# STM32H743 register map
File version: 2.4
CPU: CM7 r0p1, little endian, MPU, FPU, 4 interrupt priority bits
Registers are 32-bit, read-write, reset 0x0 unless marked. A register's access mark holds for its fields unless they carry their own. Offsets are from the block's base; [hi:lo] are bit positions; 'fields as' and 'values as' point back to an identical list.

## Flash — 闪存控制器
Base 0x52002000
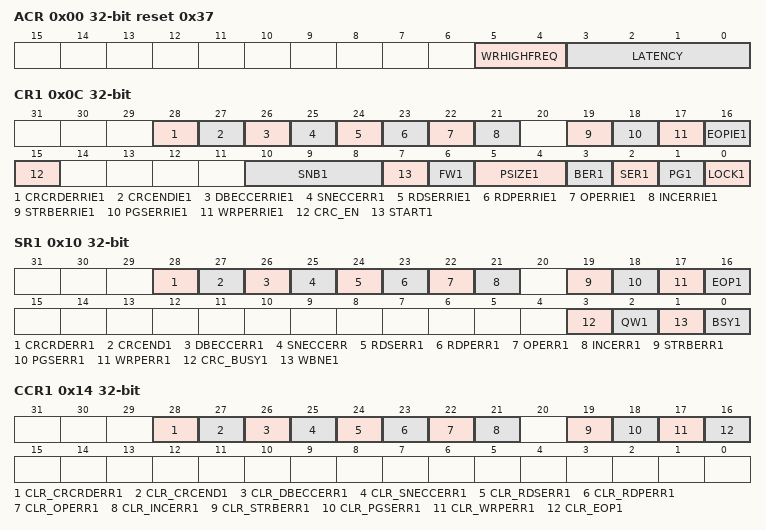
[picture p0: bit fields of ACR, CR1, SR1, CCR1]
0x00 ACR reset 0x37 — 访问控制寄存器
  [5:4] WRHIGHFREQ — 闪存信号延迟
  [3:0] LATENCY — 读延迟（等待周期）
0x04 KEYR1 — 闪存密钥寄存器（Bank 1）
  [31:0] KEY1R — Bank 1 访问配置解锁密钥
0x08 OPTKEYR — 闪存选项密钥寄存器
  [31:0] OPTKEYR — 选项字节解锁密钥
0x0C CR1 — 闪存控制寄存器（Bank 1）
  [28] CRCRDERRIE1 — Bank 1 CRC 读取错误中断使能位。当 CRCRDERRIE1 位置 1 时，若在 Bank 1 上一次 CRC 计算过程中检测到受保护区域（PCROP 或仅安全区域），则产生中断。仅当 LOCK1 清零时才能对 CRCRDERRIE1 进行编程。
  [27] CRCENDIE1 — Bank 1 CRC 计算完成中断使能位
  [26] DBECCERRIE1 — Bank 1 ECC 双比特检错中断使能位
  [25] SNECCERR1 — Bank 1 ECC 单比特纠错中断使能位
  [24] RDSERRIE1 — Bank 1 安全错误中断使能位
  [23] RDPERRIE1 — Bank 1 读保护错误中断使能位
  [22] OPERRIE1 — Bank 1 写/擦除操作错误中断使能位
  [21] INCERRIE1 — Bank 1 不一致错误中断使能位
  [19] STRBERRIE1 — Bank 1 选通错误中断使能位
  [18] PGSERRIE1 — Bank 1 编程序列错误中断使能位
  [17] WRPERRIE1 — Bank 1 写保护错误中断使能位
  [16] EOPIE1 — Bank 1 编程结束中断控制位
  [15] CRC_EN — Bank 1 CRC 控制位
  [10:8] SNB1 — Bank 1 扇区擦除编号选择
  [7] START1 — Bank 1 Bank/扇区擦除启动控制位
  [6] FW1 — Bank 1 写强制控制位
  [5:4] PSIZE1 — Bank 1 编程数据宽度
  [3] BER1 — Bank 1 整 Bank 擦除请求
  [2] SER1 — Bank 1 扇区擦除请求
  [1] PG1 — Bank 1 编程使能控制位
  [0] LOCK1 — Bank 1 配置锁定控制位
0x10 SR1 — 闪存状态寄存器（Bank 1）
  [28] CRCRDERR1 ro — Bank 1 CRC 读取错误标志位。当 Bank 1 的 CRC 操作过程中发现有字处于读保护状态时，CRCRDERR1 标志置位。若 CRCRDIE1 和 CRCEND1 均置 1，则产生中断。向 FLASH_CCR1 寄存器的 CLR_CRCRDERR1 位写 1 可清除 CRCRDERR1。注意：仅当 CRCEND1 位置 1 时，此标志才有效。
  [27] CRCEND1 — Bank 1 CRC 计算完成标志位
  [26] DBECCERR1 — Bank 1 ECC 双比特检错标志位
  [25] SNECCERR — Bank 1 ECC 单比特纠错标志位
  [24] RDSERR1 — Bank 1 安全错误标志位
  [23] RDPERR1 — Bank 1 读保护错误标志位
  [22] OPERR1 — Bank 1 写/擦除操作错误标志位
  [21] INCERR1 — Bank 1 不一致错误标志位
  [19] STRBERR1 — Bank 1 选通错误标志位
  [18] PGSERR1 — Bank 1 编程序列错误标志位
  [17] WRPERR1 — Bank 1 写保护错误标志位
  [16] EOP1 — Bank 1 编程结束标志位
  [3] CRC_BUSY1 — Bank 1 CRC 忙标志位
  [2] QW1 — Bank 1 等待队列标志位
  [1] WBNE1 — Bank 1 写缓冲区非空标志位
  [0] BSY1 — Bank 1 正在编程标志位
0x14 CCR1 — 闪存清除控制寄存器（Bank 1）
  [28] CLR_CRCRDERR1 wo — Bank 1 CRCRDERR1 标志清除位。将该位置 1 即可将 FLASH_SR1 寄存器中的 CRCRDERR1 标志复位为 0。
  [27] CLR_CRCEND1 — Bank 1 CRCEND1 标志清除位
  [26] CLR_DBECCERR1 — Bank 1 DBECCERR1 标志清除位
  [25] CLR_SNECCERR1 — Bank 1 SNECCERR1 标志清除位
  [24] CLR_RDSERR1 — Bank 1 RDSERR1 标志清除位
  [23] CLR_RDPERR1 — Bank 1 RDPERR1 标志清除位
  [22] CLR_OPERR1 — Bank 1 OPERR1 标志清除位
  [21] CLR_INCERR1 — Bank 1 INCERR1 标志清除位
  [19] CLR_STRBERR1 — Bank 1 STRBERR1 标志清除位
  [18] CLR_PGSERR1 — Bank 1 PGSERR1 标志清除位
  [17] CLR_WRPERR1 — Bank 1 WRPERR1 标志清除位
  [16] CLR_EOP1 — Bank 1 EOP1 标志清除位
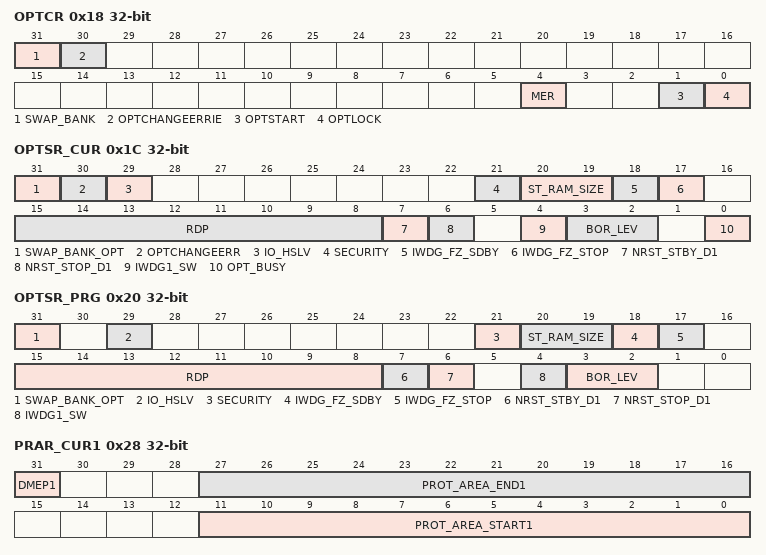
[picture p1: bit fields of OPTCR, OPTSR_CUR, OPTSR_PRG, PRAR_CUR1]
0x18 OPTCR — 闪存选项控制寄存器
  [31] SWAP_BANK — Bank 交换配置位
  [30] OPTCHANGEERRIE — 选项字节变更错误中断使能位
  [4] MER — 闪存整片擦除使能位
  [1] OPTSTART — 选项字节变更启动配置位
  [0] OPTLOCK — FLASH_OPTCR 锁定选项配置位
0x1C OPTSR_CUR — 闪存选项状态寄存器（当前值）
  [31] SWAP_BANK_OPT — Bank 交换选项状态位
  [30] OPTCHANGEERR — 选项字节变更错误标志位
  [29] IO_HSLV — I/O 低压高速状态位（PRODUCT_BELOW_25V）
  [21] SECURITY — 安全使能选项状态位
  [20:19] ST_RAM_SIZE — DTCM RAM 容量选项状态
  [18] IWDG_FZ_SDBY — IWDG Standby 模式下冻结选项状态位
  [17] IWDG_FZ_STOP — IWDG Stop 模式下冻结选项状态位
  [15:8] RDP — 读出保护级别选项状态字节
  [7] NRST_STBY_D1 — D1 域进入 DStandby 模式时复位选项状态位
  [6] NRST_STOP_D1 — D1 域进入 DStop 模式时复位选项状态位
  [4] IWDG1_SW — IWDG1 控制选项状态位
  [3:2] BOR_LEV — 欠压复位电压阈值选项状态位
  [0] OPT_BUSY — 选项字节变更进行中标志位
0x20 OPTSR_PRG — 闪存选项状态寄存器（编程值）
  [31] SWAP_BANK_OPT — Bank 交换选项配置位
  [29] IO_HSLV — I/O 低压高速模式（PRODUCT_BELOW_25V）
  [21] SECURITY — 安全选项配置位
  [20:19] ST_RAM_SIZE — DTCM 容量选择选项配置位
  [18] IWDG_FZ_SDBY — IWDG Standby 模式下冻结选项配置位
  [17] IWDG_FZ_STOP — IWDG Stop 模式下冻结选项配置位
  [15:8] RDP — 读出保护级别选项配置字节
  [7] NRST_STBY_D1 — D1 域 DStandby 后擦除选项字节配置位
  [6] NRST_STOP_D1 — D1 域 DStop 后擦除选项字节配置位
  [4] IWDG1_SW — IWDG1 选项配置位
  [3:2] BOR_LEV — BOR 复位电压阈值选项配置位
0x24 OPTCCR wo — 闪存选项清除控制寄存器
  [30] CLR_OPTCHANGEERR — OPTCHANGEERR 复位位
0x28 PRAR_CUR1 ro — 闪存保护地址寄存器（Bank 1 当前值）
  [31] DMEP1 — Bank 1 PCROP 保护区域擦除使能选项状态位
  [27:16] PROT_AREA_END1 — Bank 1 PCROP 保护区域最高地址
  [11:0] PROT_AREA_START1 — Bank 1 PCROP 保护区域最低地址
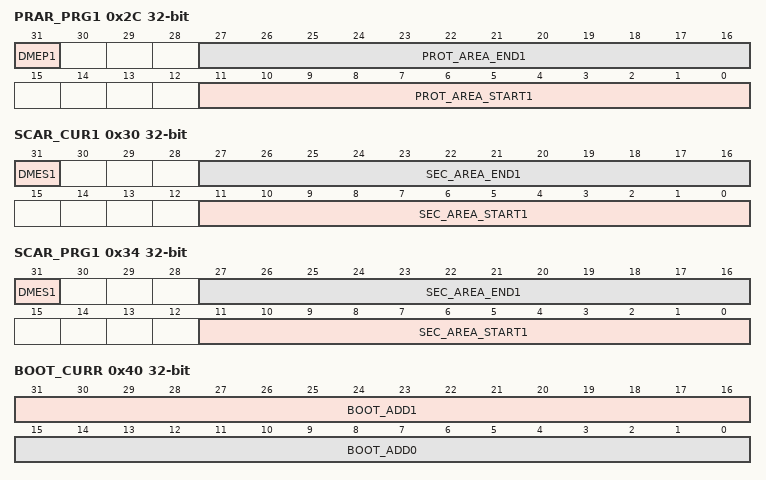
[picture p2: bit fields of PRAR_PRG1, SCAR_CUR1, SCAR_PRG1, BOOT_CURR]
0x2C PRAR_PRG1 — 闪存保护地址寄存器（Bank 1 编程值）
  [31] DMEP1 — Bank 1 PCROP 保护区域擦除使能选项配置位
  [27:16] PROT_AREA_END1 — Bank 1 PCROP 保护区域最高地址配置
  [11:0] PROT_AREA_START1 — Bank 1 PCROP 保护区域最低地址配置
0x30 SCAR_CUR1 — 闪存安全地址寄存器（Bank 1 当前值）
  [31] DMES1 — Bank 1 安全保护区域擦除使能选项状态位
  [27:16] SEC_AREA_END1 — Bank 1 安全保护区域最高地址
  [11:0] SEC_AREA_START1 — Bank 1 安全保护区域最低地址
0x34 SCAR_PRG1 — 闪存安全地址寄存器（Bank 1 编程值）
  [31] DMES1 — Bank 1 安全保护区域擦除使能选项配置位
  [27:16] SEC_AREA_END1 — Bank 1 安全保护区域最高地址配置
  [11:0] SEC_AREA_START1 — Bank 1 安全保护区域最低地址配置
0x38 WPSN_CUR1R ro — 闪存写扇区保护寄存器（Bank 1 当前值）
  [7:0] WRPSn1 — Bank 1 扇区写保护选项状态字节
0x3C WPSN_PRG1R — 闪存写扇区保护寄存器（Bank 1 编程值）
  [7:0] WRPSn1 — Bank 1 扇区写保护配置字节
0x40 BOOT_CURR ro — 闪存启动地址寄存器（当前值）
  [31:16] BOOT_ADD1 — 启动地址 1
  [15:0] BOOT_ADD0 — 启动地址 0
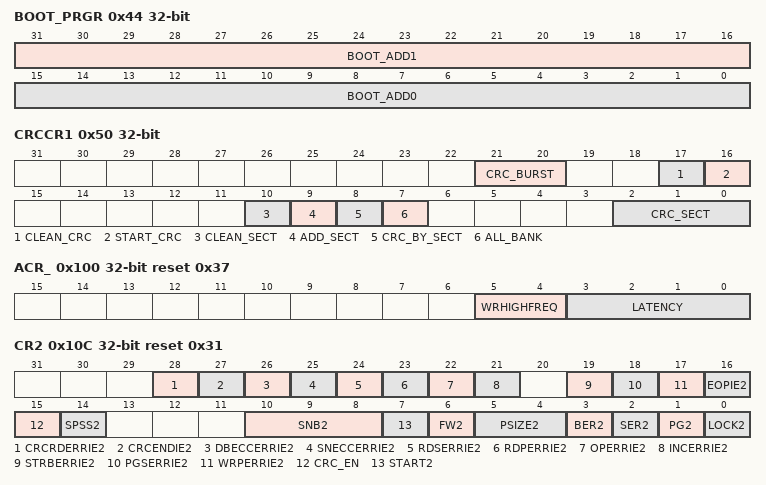
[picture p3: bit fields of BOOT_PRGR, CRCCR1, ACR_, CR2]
0x44 BOOT_PRGR ro — 闪存启动地址寄存器（编程值）
  [31:16] BOOT_ADD1 — 启动地址 1
  [15:0] BOOT_ADD0 — 启动地址 0
0x50 CRCCR1 — 闪存 CRC 控制寄存器（Bank 1）
  [21:20] CRC_BURST — Bank 1 CRC 突发大小
  [17] CLEAN_CRC — Bank 1 CRC 清除位
  [16] START_CRC — Bank 1 CRC 启动位
  [10] CLEAN_SECT — Bank 1 CRC 扇区列表清除位
  [9] ADD_SECT — Bank 1 CRC 扇区加入选择位
  [8] CRC_BY_SECT — Bank 1 CRC 扇区模式选择位
  [7] ALL_BANK — Bank 1 CRC 全 Bank 选择位
  [2:0] CRC_SECT — Bank 1 CRC 扇区编号
0x54 CRCSADD1R — 闪存 CRC 起始地址寄存器（Bank 1）
  [19:2] CRC_START_ADDR — Bank 1 CRC 起始地址
0x58 CRCEADD1R — 闪存 CRC 结束地址寄存器（Bank 1）
  [19:2] CRC_END_ADDR — Bank 1 CRC 结束地址
0x5C CRCDATAR — 闪存 CRC 数据寄存器
  [31:0] CRC_DATA — CRC 计算结果
0x60 ECC_FA1R ro — 闪存 ECC 错误地址寄存器（Bank 1）
  [14:0] FAIL_ECC_ADDR1 — Bank 1 ECC 错误地址
0x100 ACR_ reset 0x37 — 访问控制寄存器（别名）
  [5:4] WRHIGHFREQ — 闪存信号延迟
  [3:0] LATENCY — 读延迟（等待周期）
0x104 KEYR2 ro — 闪存密钥寄存器（Bank 2）
  [31:0] KEYR2 — Bank 2 访问配置解锁密钥
0x108 OPTKEYR_ — 闪存选项密钥寄存器（别名）
  [31:0] OPTKEYR — 选项字节解锁密钥
0x10C CR2 reset 0x31 — 闪存控制寄存器（Bank 2）
  [28] CRCRDERRIE2 — Bank 2 CRC 读取错误中断使能位
  [27] CRCENDIE2 — Bank 2 CRC 计算完成中断使能位
  [26] DBECCERRIE2 — Bank 2 ECC 双比特检错中断使能位
  [25] SNECCERRIE2 — Bank 2 ECC 单比特纠错中断使能位
  [24] RDSERRIE2 — Bank 2 安全错误中断使能位
  [23] RDPERRIE2 — Bank 2 读保护错误中断使能位
  [22] OPERRIE2 — Bank 2 写/擦除操作错误中断使能位
  [21] INCERRIE2 — Bank 2 不一致错误中断使能位
  [19] STRBERRIE2 — Bank 2 选通错误中断使能位
  [18] PGSERRIE2 — Bank 2 编程序列错误中断使能位
  [17] WRPERRIE2 — Bank 2 写保护错误中断使能位
  [16] EOPIE2 — Bank 2 编程结束中断控制位
  [15] CRC_EN — Bank 2 CRC 控制位
  [14] SPSS2 — Bank 2 特殊扇区选择位
  [10:8] SNB2 — Bank 2 扇区擦除编号选择
  [7] START2 — Bank 2 Bank/扇区擦除启动控制位
  [6] FW2 — Bank 2 写强制控制位
  [5:4] PSIZE2 — Bank 2 编程数据宽度
  [3] BER2 — Bank 2 整 Bank 擦除请求
  [2] SER2 — Bank 2 扇区擦除请求
  [1] PG2 — Bank 2 编程使能控制位
  [0] LOCK2 — Bank 2 配置锁定控制位
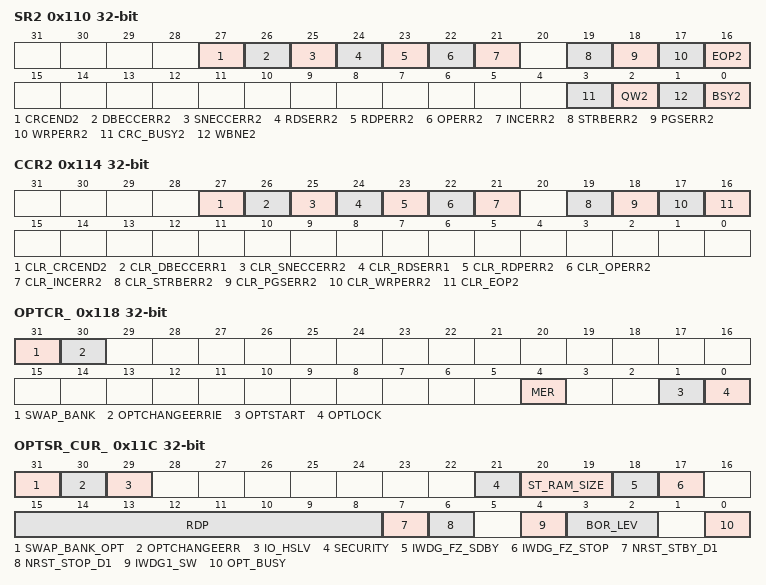
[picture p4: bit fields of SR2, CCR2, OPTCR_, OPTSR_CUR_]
0x110 SR2 — 闪存状态寄存器（Bank 2）
  [27] CRCEND2 — Bank 2 CRC 计算完成标志位
  [26] DBECCERR2 — Bank 2 ECC 双比特检错标志位
  [25] SNECCERR2 — Bank 2 ECC 单比特纠错标志位
  [24] RDSERR2 — Bank 2 安全错误标志位
  [23] RDPERR2 — Bank 2 读保护错误标志位
  [22] OPERR2 — Bank 2 写/擦除操作错误标志位
  [21] INCERR2 — Bank 2 不一致错误标志位
  [19] STRBERR2 — Bank 2 选通错误标志位
  [18] PGSERR2 — Bank 2 编程序列错误标志位
  [17] WRPERR2 — Bank 2 写保护错误标志位
  [16] EOP2 — Bank 2 编程结束标志位
  [3] CRC_BUSY2 — Bank 2 CRC 忙标志位
  [2] QW2 — Bank 2 等待队列标志位
  [1] WBNE2 — Bank 2 写缓冲区非空标志位
  [0] BSY2 — Bank 2 正在编程标志位
0x114 CCR2 — 闪存清除控制寄存器（Bank 2）
  [27] CLR_CRCEND2 — Bank 2 CRCEND2 标志清除位
  [26] CLR_DBECCERR1 — Bank 1 DBECCERR1 flag clear bit
  [25] CLR_SNECCERR2 — Bank 2 SNECCERR2 标志清除位
  [24] CLR_RDSERR1 — Bank 1 RDSERR1 flag clear bit
  [23] CLR_RDPERR2 — Bank 2 RDPERR2 标志清除位
  [22] CLR_OPERR2 — Bank 2 OPERR2 标志清除位
  [21] CLR_INCERR2 — Bank 2 INCERR2 标志清除位
  [19] CLR_STRBERR2 — Bank 2 STRBERR2 标志清除位
  [18] CLR_PGSERR2 — Bank 2 PGSERR2 标志清除位
  [17] CLR_WRPERR2 — Bank 2 WRPERR2 标志清除位
  [16] CLR_EOP2 — Bank 2 EOP2 标志清除位
0x118 OPTCR_ — 闪存选项控制寄存器（别名）
  fields as OPTCR
0x11C OPTSR_CUR_ — 闪存选项状态寄存器（当前值）（别名）
  fields as OPTSR_CUR
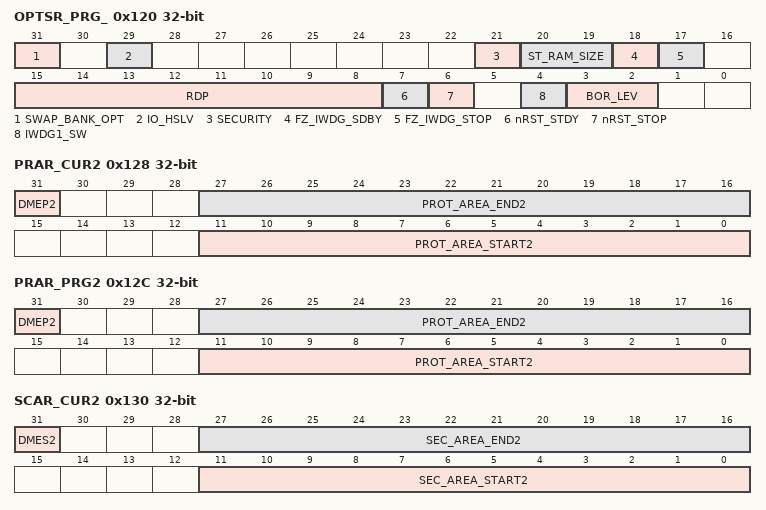
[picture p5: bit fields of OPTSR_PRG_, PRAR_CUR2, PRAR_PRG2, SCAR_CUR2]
0x120 OPTSR_PRG_ — 闪存选项状态寄存器（编程值）（别名）
  [31] SWAP_BANK_OPT — Bank 交换选项配置位
  [29] IO_HSLV — I/O 低压高速模式（PRODUCT_BELOW_25V）
  [21] SECURITY — 安全选项配置位
  [20:19] ST_RAM_SIZE — DTCM 容量选择选项配置位
  [18] FZ_IWDG_SDBY — IWDG Standby 模式下冻结选项配置位
  [17] FZ_IWDG_STOP — IWDG Stop 模式下冻结选项配置位
  [15:8] RDP — 读出保护级别选项配置字节
  [7] nRST_STDY — D1 域 DStandby 后擦除选项字节配置位
  [6] nRST_STOP — D1 域 DStop 后擦除选项字节配置位
  [4] IWDG1_SW — IWDG1 选项配置位
  [3:2] BOR_LEV — BOR 复位电压阈值选项配置位
0x124 OPTCCR_ wo — 闪存选项清除控制寄存器（别名）
  [30] CLR_OPTCHANGEERR — OPTCHANGEERR 复位位
0x128 PRAR_CUR2 ro — 闪存保护地址寄存器（Bank 2 当前值）
  [31] DMEP2 — Bank 2 PCROP 保护区域擦除使能选项状态位
  [27:16] PROT_AREA_END2 — Bank 2 PCROP 保护区域最高地址
  [11:0] PROT_AREA_START2 — Bank 2 PCROP 保护区域最低地址
0x12C PRAR_PRG2 (alternate view of PRAR_PRG1) — 闪存保护地址寄存器（Bank 2 编程值）
  [31] DMEP2 — Bank 2 PCROP 保护区域擦除使能选项配置位
  [27:16] PROT_AREA_END2 — Bank 2 PCROP 保护区域最高地址配置
  [11:0] PROT_AREA_START2 — Bank 2 PCROP 保护区域最低地址配置
0x130 SCAR_CUR2 — 闪存安全地址寄存器（Bank 2 当前值）
  [31] DMES2 — Bank 2 安全保护区域擦除使能选项状态位
  [27:16] SEC_AREA_END2 — Bank 2 安全保护区域最高地址
  [11:0] SEC_AREA_START2 — Bank 2 安全保护区域最低地址
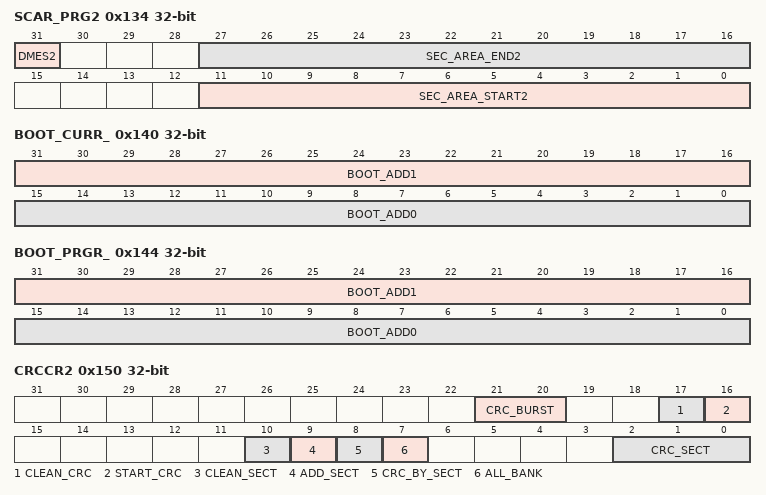
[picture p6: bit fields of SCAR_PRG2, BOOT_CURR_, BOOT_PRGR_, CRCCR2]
0x134 SCAR_PRG2 — 闪存安全地址寄存器（Bank 2 编程值）
  [31] DMES2 — Bank 2 安全保护区域擦除使能选项配置位
  [27:16] SEC_AREA_END2 — Bank 2 安全保护区域最高地址配置
  [11:0] SEC_AREA_START2 — Bank 2 安全保护区域最低地址配置
0x138 WPSN_CUR2R ro — 闪存写扇区保护寄存器（Bank 2 当前值）
  [7:0] WRPSn2 — Bank 2 扇区写保护选项状态字节
0x13C WPSN_PRG2R — 闪存写扇区保护寄存器（Bank 2 编程值）
  [7:0] WRPSn2 — Bank 2 扇区写保护配置字节
0x140 BOOT_CURR_ ro — 闪存启动地址寄存器（当前值）（别名）
  [31:16] BOOT_ADD1 — 启动地址 1
  [15:0] BOOT_ADD0 — 启动地址 0
0x144 BOOT_PRGR_ ro — 闪存启动地址寄存器（编程值）（别名）
  [31:16] BOOT_ADD1 — 启动地址 1
  [15:0] BOOT_ADD0 — 启动地址 0
0x150 CRCCR2 — 闪存 CRC 控制寄存器（Bank 2）
  [21:20] CRC_BURST — Bank 2 CRC 突发大小
  [17] CLEAN_CRC — Bank 2 CRC 清除位
  [16] START_CRC — Bank 2 CRC 启动位
  [10] CLEAN_SECT — Bank 2 CRC 扇区列表清除位
  [9] ADD_SECT — Bank 2 CRC 扇区加入选择位
  [8] CRC_BY_SECT — Bank 2 CRC 扇区模式选择位
  [7] ALL_BANK — Bank 2 CRC 全 Bank 选择位
  [2:0] CRC_SECT — Bank 2 CRC 扇区编号
0x154 CRCSADD2R — 闪存 CRC 起始地址寄存器（Bank 2）
  [19:2] CRC_START_ADDR — Bank 2 CRC 起始地址
0x158 CRCEADD2R — 闪存 CRC 结束地址寄存器（Bank 2）
  [19:2] CRC_END_ADDR — Bank 2 CRC 结束地址
0x15C CRCDATAR_ — 闪存 CRC 数据寄存器（别名）
  [31:0] CRC_DATA — CRC 计算结果
0x160 ECC_FA2R ro — 闪存 ECC 错误地址寄存器（Bank 2）
  [14:0] FAIL_ECC_ADDR2 — Bank 2 ECC 错误地址
